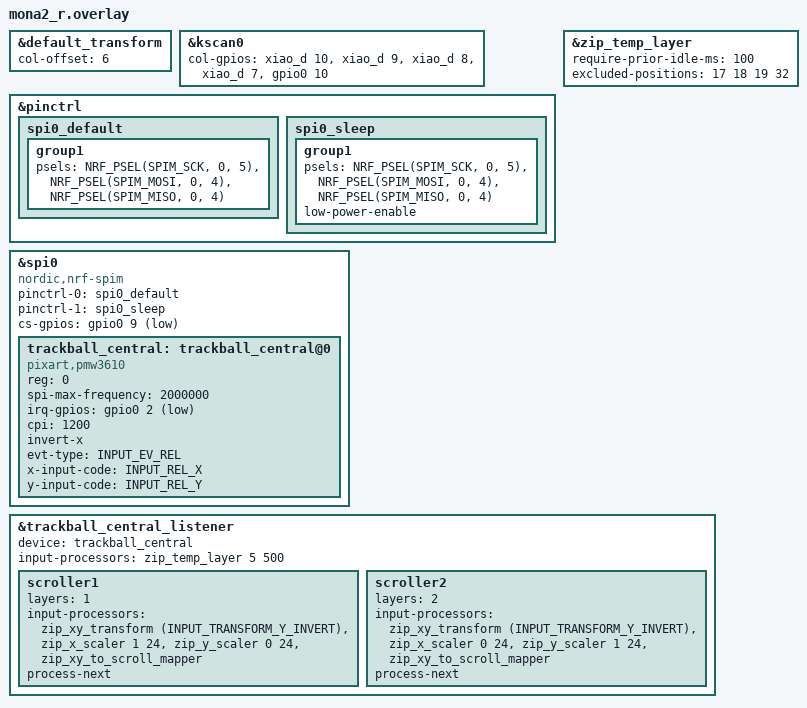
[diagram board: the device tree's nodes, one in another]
#include "mona2.dtsi"
#include <input/processors.dtsi>
#include <zephyr/dt-bindings/input/input-event-codes.h>


&default_transform {
    col-offset = <6>;
};

&kscan0 {
        col-gpios
            = <&xiao_d 10 GPIO_ACTIVE_HIGH>
            , <&xiao_d 9 GPIO_ACTIVE_HIGH> 
            , <&xiao_d 8 GPIO_ACTIVE_HIGH> 
            , <&xiao_d 7 GPIO_ACTIVE_HIGH> 
            , <&gpio0 10 GPIO_ACTIVE_HIGH>
            ;
};


&pinctrl {
    spi0_default: spi0_default {    //通常時(SPI通信中)のピン構成
        group1 {
            psels = <NRF_PSEL(SPIM_SCK, 0, 5)>, //P0.05を指定(SCLK)
                <NRF_PSEL(SPIM_MOSI, 0, 4)>,    //P0.04を指定(SDIOだからMOSI,MISO両方の役割を担う)
                <NRF_PSEL(SPIM_MISO, 0, 4)>;
        };
    };

    spi0_sleep: spi0_sleep {    //スリープ時のピン構成(省電力)
        group1 {
            psels = <NRF_PSEL(SPIM_SCK, 0, 5)>,
                <NRF_PSEL(SPIM_MOSI, 0, 4)>,
                <NRF_PSEL(SPIM_MISO, 0, 4)>;
            low-power-enable;
        };
    };
};


&spi0 {
    status = "okay";
    compatible = "nordic,nrf-spim"; //マイコンがnRFシリーズ
    pinctrl-0 = <&spi0_default>;
    pinctrl-1 = <&spi0_sleep>;
    pinctrl-names = "default", "sleep";
    cs-gpios = <&gpio0 9 GPIO_ACTIVE_LOW>;  //P0.09を指定(CS)

    trackball_central: trackball_central@0 {
        status = "okay";
        compatible = "pixart,pmw3610";  //トラボセンサ用のドライバとバインド
        reg = <0>;
        spi-max-frequency = <2000000>;
        irq-gpios = <&gpio0 2 (GPIO_ACTIVE_LOW | GPIO_PULL_UP)>; //P0.02を指定(MOTION)
        cpi = <1200>;  // マウス感度
        //swap-xy;
        invert-x; //COROPIT版ではコメントアウトを外す
        //invert-y; //COROPIT版ではコメントアウトを外す
        evt-type = <INPUT_EV_REL>;
        x-input-code = <INPUT_REL_X>;
        y-input-code = <INPUT_REL_Y>;
    };
};

&zip_temp_layer {
   require-prior-idle-ms = <100>; // キーボード操作後AML無効時間
   excluded-positions = <
       17 // J
       18 // K
       19 // L
       32 // Shift
   >;
};

// Overrides for the input listener node
&trackball_central_listener {
    status = "okay";
    device = <&trackball_central>;
    input-processors = <&zip_temp_layer 5 500>;  // オートマウスレイヤー（AML）: トラックボール動作時に自動的にレイヤー5を有効化（500ms）

    scroller1 {
        layers = <1>; // オートスクロールレイヤー（横スクロールのみ）
        input-processors =
            <&zip_xy_transform (INPUT_TRANSFORM_Y_INVERT)>,
            <&zip_x_scaler 1 24>,
            <&zip_y_scaler 0 24>,
            <&zip_xy_to_scroll_mapper>;
        process-next;
    };
    scroller2 {
        layers = <2>; // オートスクロールレイヤー（縦スクロールのみ）
        input-processors =
            <&zip_xy_transform (INPUT_TRANSFORM_Y_INVERT)>,
            <&zip_x_scaler 0 24>,
            <&zip_y_scaler 1 24>,
            <&zip_xy_to_scroll_mapper>;
        process-next;
    };
};
